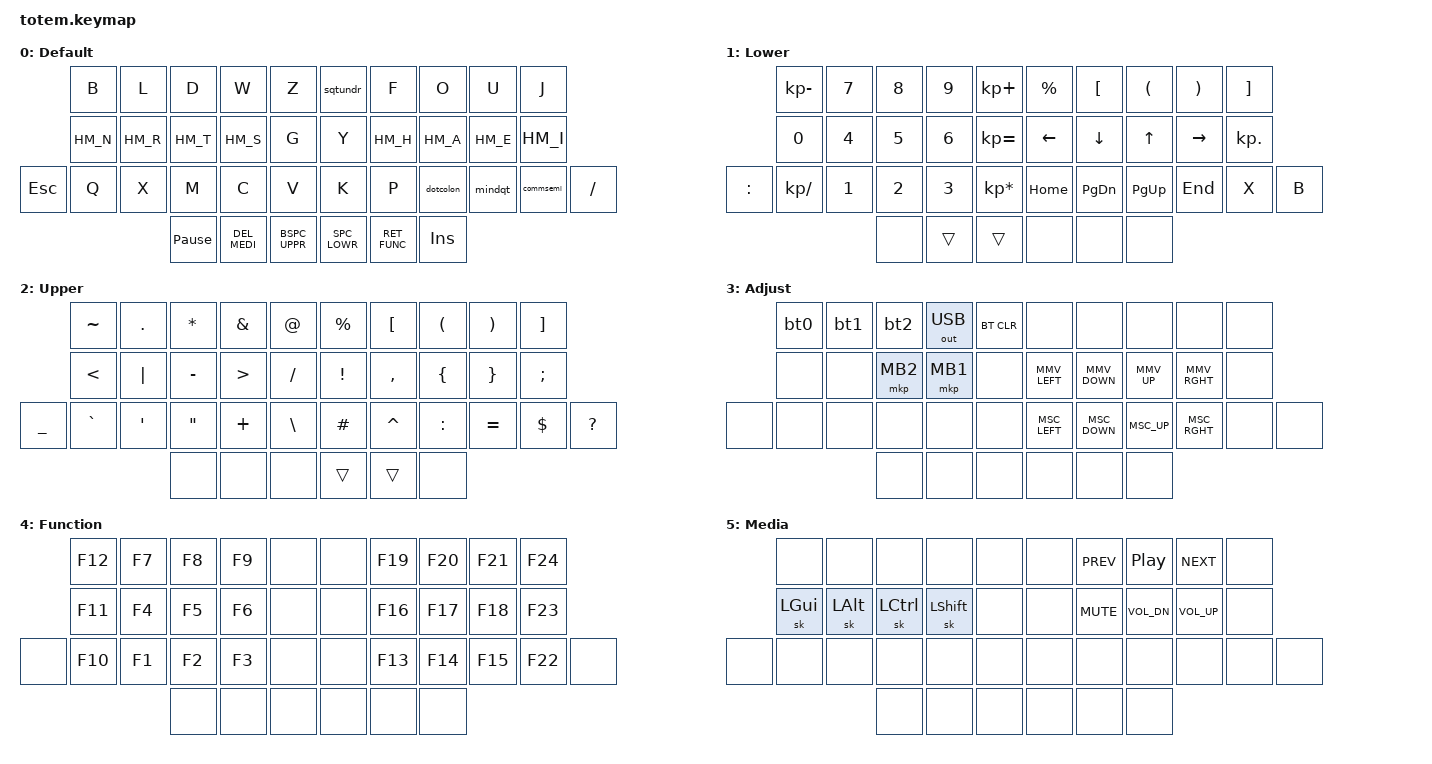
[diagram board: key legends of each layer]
#include <behaviors.dtsi>
#include <dt-bindings/zmk/keys.h>
#include <dt-bindings/zmk/bt.h>
#include <dt-bindings/zmk/outputs.h>

#include <zmk-helpers/helper.h>
#include <zmk-helpers/key-labels/totem.h>

#include "mouse.h"

#define KEYS_L LT0 LT1 LT2 LT3 LT4 LM0 LM1 LM2 LM3 LM4 LB0 LB1 LB2 LB3 LB4 LB5 LH0 LH1 LH2
#define KEYS_R RT0 RT1 RT2 RT3 RT4 RM0 RM1 RM2 RM3 RM4 RB0 RB1 RB2 RB3 RB4 RB5 RH0 RH1 RH2

#include "keymap.dtsi"

/* Base (default), Graphite alphas
 */
ZMK_LAYER(Default,
               &kp B        &kp L        &kp D        &kp W        &kp Z          &sqtundr     &kp F        &kp O        &kp U        &kp J
               HM_N         HM_R         HM_T         HM_S         &kp G          &kp Y        HM_H         HM_A         HM_E         HM_I
  &kp ESC      &kp Q        &kp X        &kp M        &kp C        &kp V          &kp K        &kp P        &dotcolon    &mindqt      &commsemi    &kp FSLH

                                      &kp PAUSE_BREAK DEL_MEDI     BSPC_UPPR      SPC_LOWR     RET_FUNC     &kp INS
)

/* Numbers, Navigation
 */
ZMK_LAYER(Lower,
               &kp KP_MINUS &kp N7       &kp N8       &kp N9       &kp KP_PLUS    &kp PRCNT    &kp LBKT     &kp LPAR     &kp RPAR     &kp RBKT
               &kp N0       &kp N4       &kp N5       &kp N6       &kp KP_EQUAL   &kp LEFT     &kp DOWN     &kp UP       &kp RIGHT    &kp KP_DOT
  &kp COLON    &kp KP_SLASH &kp N1       &kp N2       &kp N3       &kp KP_ASTERISK &kp HOME    &kp PG_DN    &kp PG_UP    &kp END      &kp X        &kp B

                                         &none        &trans       &trans         &none        &none        &none
)

/* Symbols
 */
ZMK_LAYER(Upper,
               &kp TILDE    &kp DOT      &kp ASTRK    &kp AMPS     &kp AT         &kp PRCNT    &kp LBKT     &kp LPAR     &kp RPAR     &kp RBKT
               &kp LT       &kp PIPE     &kp MINUS    &kp GT       &kp FSLH       &kp EXCL     &kp COMMA    &kp LBRC     &kp RBRC     &kp SEMI
  &kp UNDER    &kp GRAVE    &kp SQT      &kp DQT      &kp PLUS     &kp BSLH       &kp HASH     &kp CARET    &kp COLON    &kp EQUAL    &kp DLLR     &kp QMARK

                                         &none        &none        &none          &trans       &trans       &none
)

/* Mouse, Keyboard control
 */
ZMK_LAYER(Adjust,
               &bt0         &bt1         &bt2         &out OUT_USB &bt BT_CLR     &none        &none        &none        &none        &none
               &none        &none        &mkp MB2     &mkp MB1     &none          MMV_LEFT     MMV_DOWN     MMV_UP       MMV_RGHT     &none
  &none        &none        &none        &none        &none        &none          MSC_LEFT     MSC_DOWN     MSC_UP       MSC_RGHT     &none        &none

                                         &none        &none        &none          &none        &none        &none
)

/* Function keys
 */
ZMK_LAYER(Function,
               &kp F12      &kp F7       &kp F8       &kp F9       &none          &none        &kp F19      &kp F20      &kp F21      &kp F24
               &kp F11      &kp F4       &kp F5       &kp F6       &none          &none        &kp F16      &kp F17      &kp F18      &kp F23
  &none        &kp F10      &kp F1       &kp F2       &kp F3       &none          &none        &kp F13      &kp F14      &kp F15      &kp F22      &none

                                         &none        &none        &none          &none        &none        &none
)

/* Media, One-shot modifiers
 */
ZMK_LAYER(Media,
               &none        &none        &none        &none        &none          &none        &kp C_PREV   &kp C_PP     &kp C_NEXT   &none
               &sk LGUI     &sk LALT     &sk LCTRL    &sk LSHFT    &none          &none        &kp C_MUTE   &kp C_VOL_DN &kp C_VOL_UP &none
  &none        &none        &none        &none        &none        &none          &none        &none        &none        &none        &none        &none

                                         &none        &none        &none          &none        &none        &none
)
